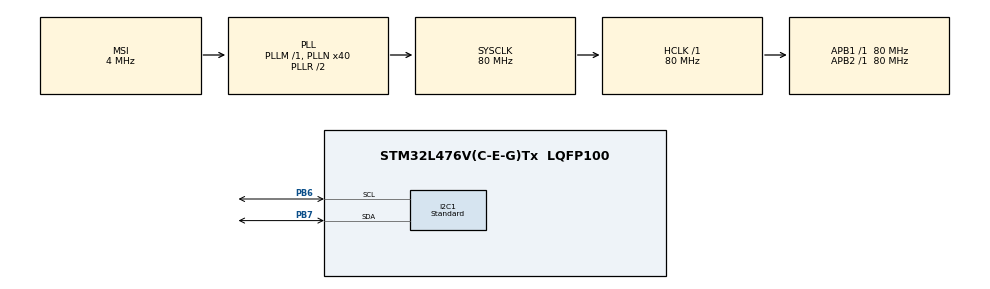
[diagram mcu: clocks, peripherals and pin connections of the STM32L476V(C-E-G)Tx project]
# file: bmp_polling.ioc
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I2C1.I2C_Speed_Mode=I2C_Standard
I2C1.Timing=0x10909CEC
Mcu.Family=STM32L4
Mcu.Name=STM32L476V(C-E-G)Tx
Mcu.Package=LQFP100
NVIC.PriorityGroup=NVIC_PRIORITYGROUP_4
PB6.Mode=I2C
PB6.Signal=I2C1_SCL
PB7.Mode=I2C
PB7.Signal=I2C1_SDA
PH0-OSC_IN\ (PH0).Mode=HSE-External-Oscillator
PH0-OSC_IN\ (PH0).Signal=RCC_OSC_IN
PH1-OSC_OUT\ (PH1).Mode=HSE-External-Oscillator
PH1-OSC_OUT\ (PH1).Signal=RCC_OSC_OUT
ProjectManager.HeapSize=0x200
ProjectManager.StackSize=0x400
ProjectManager.TargetToolchain=EWARM V8
RCC.ADCFreq_Value=48000000
RCC.AHBFreq_Value=80000000
RCC.APB1Freq_Value=80000000
RCC.APB1TimFreq_Value=80000000
RCC.APB2Freq_Value=80000000
RCC.APB2TimFreq_Value=80000000
RCC.CortexFreq_Value=80000000
RCC.HCLKFreq_Value=80000000
RCC.HSE_VALUE=24000000
RCC.HSI_VALUE=16000000
RCC.MSI_VALUE=4000000
RCC.PLLM=6
RCC.PLLN=40
RCC.PLLSAI1N=24
RCC.PLLSourceVirtual=RCC_PLLSOURCE_HSE
RCC.PREFETCH_ENABLE=1
RCC.SYSCLKFreq_VALUE=80000000
RCC.SYSCLKSource=RCC_SYSCLKSOURCE_PLLCLK
RCC.USBFreq_Value=48000000
RCC.VCOOutputFreq_Value=160000000
board=STM32L476G-DISCO

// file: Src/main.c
/* USER CODE BEGIN Header */
/**
  ******************************************************************************
  * @file           : main.c
  * @brief          : Main program body
  ******************************************************************************
  * @attention
  *
  * <h2><center>&copy; Copyright (c) 2019 STMicroelectronics.
  * All rights reserved.</center></h2>
  *
  * This software component is licensed by ST under BSD 3-Clause license,
  * the "License"; You may not use this file except in compliance with the
  * License. You may obtain a copy of the License at:
  *                        opensource.org/licenses/BSD-3-Clause
  *
  ******************************************************************************
  */
/* USER CODE END Header */

#include "main.h"

/* USER CODE BEGIN Includes */
#include "bmp280.h"
/* USER CODE END Includes */

/* USER CODE BEGIN PD */
/**
 * BMP280 or BME280 address is 0x77 if SDO pin is high, and is 0x76 if
 * SDO pin is low.
 */
#define BMP280_I2C_ADDRESS_0  0x76
#define BMP280_I2C_ADDRESS_1  0x77
/* USER CODE END PD */

I2C_HandleTypeDef hi2c1;

/* USER CODE BEGIN PV */
BMP280_HandleTypedef bmp280;

float pressure, temperature, humidity;

bool bme280p;
/* USER CODE END PV */

void SystemClock_Config(void);
static void MX_GPIO_Init(void);
static void MX_I2C1_Init(void);
static void MX_BMP_Init(void);

int main(void)
{

  /* MCU Configuration--------------------------------------------------------*/

  /* Reset of all peripherals, Initializes the Flash interface and the Systick. */
  HAL_Init();

  /* Configure the system clock */
  SystemClock_Config();

  /* Initialize all configured peripherals */
  MX_GPIO_Init();
  MX_I2C1_Init();
  /* USER CODE BEGIN 2 */
  MX_BMP_Init();
  /* USER CODE END 2 */

  /* Infinite loop */
  /* USER CODE BEGIN WHILE */
  while (1)
  {
    HAL_Delay(100);
    while (!bmp280_read_float(&bmp280, &temperature, &pressure, &humidity))
    {
      printf("Temperature/pressure reading failed\n");
      HAL_Delay(2000);
    }

    printf("Pressure: %.2f Pa, Temperature: %.2f C", pressure, temperature);
    if (bme280p == true)
    {
      printf(", Humidity: %.2f\n", humidity);
    }
    else
    {
      printf("\n");
    }
    HAL_Delay(2000);
    /* USER CODE END WHILE */

  }
}

void SystemClock_Config(void)
{
  RCC_ClkInitTypeDef RCC_ClkInitStruct = {0};
  RCC_OscInitTypeDef RCC_OscInitStruct = {0};

  /* MSI is enabled after System reset, activate PLL with MSI as source */
  RCC_OscInitStruct.OscillatorType = RCC_OSCILLATORTYPE_MSI;
  RCC_OscInitStruct.MSIState = RCC_MSI_ON;
  RCC_OscInitStruct.MSIClockRange = RCC_MSIRANGE_6;
  RCC_OscInitStruct.MSICalibrationValue = RCC_MSICALIBRATION_DEFAULT;
  RCC_OscInitStruct.PLL.PLLState = RCC_PLL_ON;
  RCC_OscInitStruct.PLL.PLLSource = RCC_PLLSOURCE_MSI;
  RCC_OscInitStruct.PLL.PLLM = 1;
  RCC_OscInitStruct.PLL.PLLN = 40;
  RCC_OscInitStruct.PLL.PLLR = 2;
  RCC_OscInitStruct.PLL.PLLP = 7;
  RCC_OscInitStruct.PLL.PLLQ = 4;
  if(HAL_RCC_OscConfig(&RCC_OscInitStruct) != HAL_OK)
  {
    /* Initialization Error */
    while(1);
  }

  /* Select PLL as system clock source and configure the HCLK, PCLK1 and PCLK2
     clocks dividers */
  RCC_ClkInitStruct.ClockType = (RCC_CLOCKTYPE_SYSCLK | RCC_CLOCKTYPE_HCLK | RCC_CLOCKTYPE_PCLK1 | RCC_CLOCKTYPE_PCLK2);
  RCC_ClkInitStruct.SYSCLKSource = RCC_SYSCLKSOURCE_PLLCLK;
  RCC_ClkInitStruct.AHBCLKDivider = RCC_SYSCLK_DIV1;
  RCC_ClkInitStruct.APB1CLKDivider = RCC_HCLK_DIV1;
  RCC_ClkInitStruct.APB2CLKDivider = RCC_HCLK_DIV1;
  if(HAL_RCC_ClockConfig(&RCC_ClkInitStruct, FLASH_LATENCY_4) != HAL_OK)
  {
    /* Initialization Error */
    while(1);
  }
}

static void MX_I2C1_Init(void)
{

  hi2c1.Instance = I2C1;
  hi2c1.Init.Timing = 0x10909CEC;
  hi2c1.Init.OwnAddress1 = 0;
  hi2c1.Init.AddressingMode = I2C_ADDRESSINGMODE_7BIT;
  hi2c1.Init.DualAddressMode = I2C_DUALADDRESS_DISABLE;
  hi2c1.Init.OwnAddress2 = 0;
  hi2c1.Init.OwnAddress2Masks = I2C_OA2_NOMASK;
  hi2c1.Init.GeneralCallMode = I2C_GENERALCALL_DISABLE;
  hi2c1.Init.NoStretchMode = I2C_NOSTRETCH_DISABLE;
  if (HAL_I2C_Init(&hi2c1) != HAL_OK)
  {
    Error_Handler();
  }
  /** Configure Analogue filter
  */
  if (HAL_I2CEx_ConfigAnalogFilter(&hi2c1, I2C_ANALOGFILTER_ENABLE) != HAL_OK)
  {
    Error_Handler();
  }
  /** Configure Digital filter
  */
  if (HAL_I2CEx_ConfigDigitalFilter(&hi2c1, 0) != HAL_OK)
  {
    Error_Handler();
  }

}

static void MX_GPIO_Init(void)
{

  /* GPIO Ports Clock Enable */
  __HAL_RCC_GPIOH_CLK_ENABLE();
  __HAL_RCC_GPIOB_CLK_ENABLE();

}

/* USER CODE BEGIN 4 */
static void MX_BMP_Init(void)
{
  bmp280_init_default_params(&bmp280.params);
  bmp280.addr = BMP280_I2C_ADDRESS_1;
  bmp280.i2c = &hi2c1;

  while (!bmp280_init(&bmp280, &bmp280.params))
  {
    printf("BMP280 initialization failed\n");
    HAL_Delay(2000);
  }
  bme280p = bmp280.id == BMP280_CHIP_ID;
  if (bme280p == true)
  {
    printf("BMP280: found BMP280\n");
  }
  else
  {
    printf("BMP280: found BME280\n");
  }
}

/* USER CODE END 4 */

void Error_Handler(void)
{
  /* USER CODE BEGIN Error_Handler_Debug */
  /* User can add his own implementation to report the HAL error return state */
  printf("Error\n");
  /* USER CODE END Error_Handler_Debug */
}

/************************ (C) COPYRIGHT STMicroelectronics *****END OF FILE****/
